# STM32L071 register map
File version: 1.3
CPU: CM0+ r0p0, little endian, no MPU, no FPU, 3 interrupt priority bits
Registers are 32-bit, read-write, reset 0x0 unless marked. A register's access mark holds for its fields unless they carry their own. Offsets are from the block's base; [hi:lo] are bit positions; {n}, {i} and the like mark numbered series; 'fields as' and 'values as' point back to an identical list.

## RTC — Real-time clock
Base 0x40002800
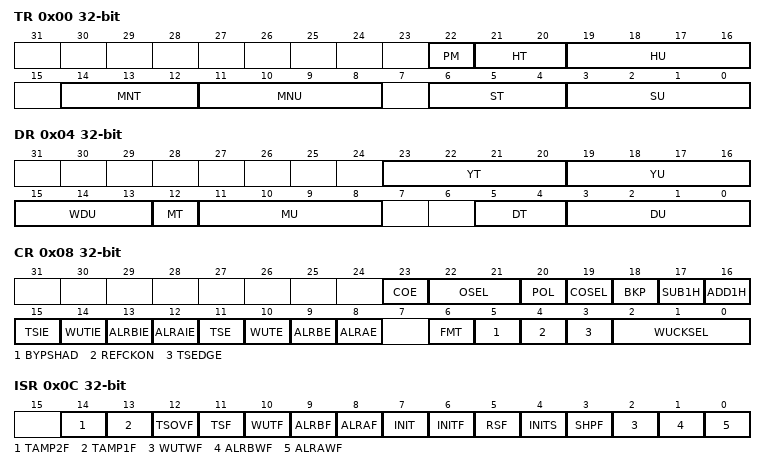
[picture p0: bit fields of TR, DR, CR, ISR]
0x00 TR — RTC time register
  [22] PM — AM/PM notation
  [21:20] HT — Hour tens in BCD format
  [19:16] HU — Hour units in BCD format
  [14:12] MNT — Minute tens in BCD format
  [11:8] MNU — Minute units in BCD format
  [6:4] ST — Second tens in BCD format
  [3:0] SU — Second units in BCD format
0x04 DR — RTC date register
  [23:20] YT — Year tens in BCD format
  [19:16] YU — Year units in BCD format
  [15:13] WDU — Week day units
  [12] MT — Month tens in BCD format
  [11:8] MU — Month units in BCD format
  [5:4] DT — Date tens in BCD format
  [3:0] DU — Date units in BCD format
0x08 CR access per field — RTC control register
  [23] COE rw — Calibration output enable
  [22:21] OSEL rw — Output selection
  [20] POL rw — Output polarity
  [19] COSEL rw — Calibration output selection
  [18] BKP rw — Backup
  [17] SUB1H wo — Subtract 1 hour (winter time change)
  [16] ADD1H wo — Add 1 hour (summer time change)
  [15] TSIE rw — Time-stamp interrupt enable
  [14] WUTIE rw — Wakeup timer interrupt enable
  [13] ALRBIE rw — Alarm B interrupt enable
  [12] ALRAIE rw — Alarm A interrupt enable
  [11] TSE rw — timestamp enable
  [10] WUTE rw — Wakeup timer enable
  [9] ALRBE rw — Alarm B enable
  [8] ALRAE rw — Alarm A enable
  [6] FMT rw — Hour format
  [5] BYPSHAD rw — Bypass the shadow registers
  [4] REFCKON rw — RTC_REFIN reference clock detection enable (50 or 60 Hz)
  [3] TSEDGE rw — Time-stamp event active edge
  [2:0] WUCKSEL rw — Wakeup clock selection
0x0C ISR access per field — RTC initialization and status register
  [14] TAMP2F rw — RTC_TAMP2 detection flag
  [13] TAMP1F rw — RTC_TAMP1 detection flag
  [12] TSOVF rw — Time-stamp overflow flag
  [11] TSF rw — Time-stamp flag
  [10] WUTF rw — Wakeup timer flag
  [9] ALRBF rw — Alarm B flag
  [8] ALRAF rw — Alarm A flag
  [7] INIT rw — Initialization mode
  [6] INITF ro — Initialization flag
  [5] RSF rw — Registers synchronization flag
  [4] INITS ro — Initialization status flag
  [3] SHPF ro — Shift operation pending
  [2] WUTWF ro — Wakeup timer write flag
  [1] ALRBWF ro — Alarm B write flag
  [0] ALRAWF ro — Alarm A write flag
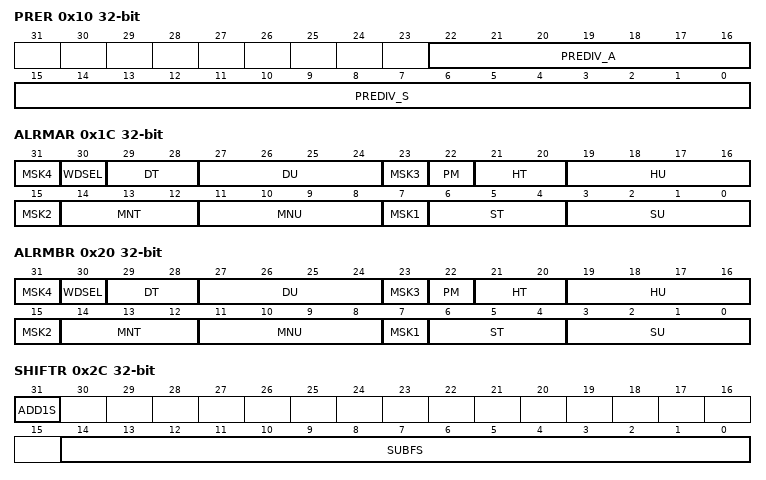
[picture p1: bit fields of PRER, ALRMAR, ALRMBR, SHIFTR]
0x10 PRER — RTC prescaler register
  [22:16] PREDIV_A — Asynchronous prescaler factor
  [15:0] PREDIV_S — Synchronous prescaler factor
0x14 WUTR — RTC wakeup timer register
  [15:0] WUT — Wakeup auto-reload value bits
0x1C ALRMAR — RTC alarm A register
  [31] MSK4 — Alarm A date mask
  [30] WDSEL — Week day selection
  [29:28] DT — Date tens in BCD format.
  [27:24] DU — Date units or day in BCD format.
  [23] MSK3 — Alarm A hours mask
  [22] PM — AM/PM notation
  [21:20] HT — Hour tens in BCD format.
  [19:16] HU — Hour units in BCD format.
  [15] MSK2 — Alarm A minutes mask
  [14:12] MNT — Minute tens in BCD format.
  [11:8] MNU — Minute units in BCD format.
  [7] MSK1 — Alarm A seconds mask
  [6:4] ST — Second tens in BCD format.
  [3:0] SU — Second units in BCD format.
0x20 ALRMBR — RTC alarm B register
  [31] MSK4 — Alarm B date mask
  [30] WDSEL — Week day selection
  [29:28] DT — Date tens in BCD format
  [27:24] DU — Date units or day in BCD format
  [23] MSK3 — Alarm B hours mask
  [22] PM — AM/PM notation
  [21:20] HT — Hour tens in BCD format
  [19:16] HU — Hour units in BCD format
  [15] MSK2 — Alarm B minutes mask
  [14:12] MNT — Minute tens in BCD format
  [11:8] MNU — Minute units in BCD format
  [7] MSK1 — Alarm B seconds mask
  [6:4] ST — Second tens in BCD format
  [3:0] SU — Second units in BCD format
0x24 WPR wo — write protection register
  [7:0] KEY — Write protection key
0x28 SSR ro — RTC sub second register
  [15:0] SS — Sub second value
0x2C SHIFTR wo — RTC shift control register
  [31] ADD1S — Add one second
  [14:0] SUBFS — Subtract a fraction of a second
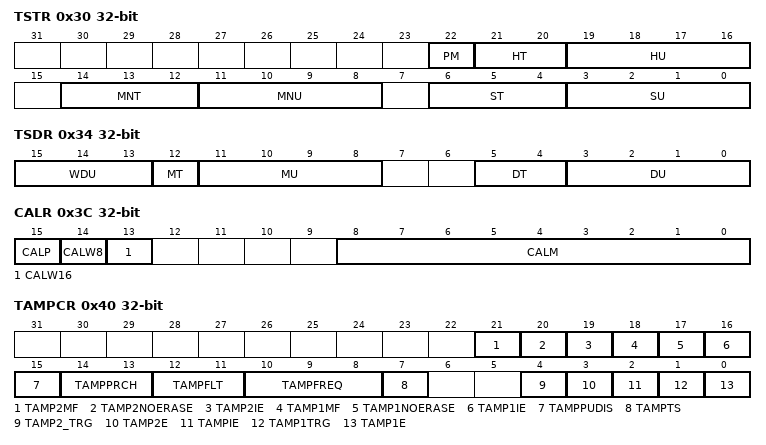
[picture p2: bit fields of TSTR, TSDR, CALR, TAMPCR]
0x30 TSTR ro — RTC timestamp time register
  [22] PM — AM/PM notation
  [21:20] HT — Hour tens in BCD format.
  [19:16] HU — Hour units in BCD format.
  [14:12] MNT — Minute tens in BCD format.
  [11:8] MNU — Minute units in BCD format.
  [6:4] ST — Second tens in BCD format.
  [3:0] SU — Second units in BCD format.
0x34 TSDR ro — RTC timestamp date register
  [15:13] WDU — Week day units
  [12] MT — Month tens in BCD format
  [11:8] MU — Month units in BCD format
  [5:4] DT — Date tens in BCD format
  [3:0] DU — Date units in BCD format
0x38 TSSSR ro — RTC time-stamp sub second register
  [15:0] SS — Sub second value
0x3C CALR — RTC calibration register
  [15] CALP — Increase frequency of RTC by 488.5 ppm
  [14] CALW8 — Use an 8-second calibration cycle period
  [13] CALW16 — Use a 16-second calibration cycle period
  [8:0] CALM — Calibration minus
0x40 TAMPCR — RTC tamper configuration register
  [21] TAMP2MF — Tamper 2 mask flag
  [20] TAMP2NOERASE — Tamper 2 no erase
  [19] TAMP2IE — Tamper 2 interrupt enable
  [18] TAMP1MF — Tamper 1 mask flag
  [17] TAMP1NOERASE — Tamper 1 no erase
  [16] TAMP1IE — Tamper 1 interrupt enable
  [15] TAMPPUDIS — RTC_TAMPx pull-up disable
  [14:13] TAMPPRCH — RTC_TAMPx precharge duration
  [12:11] TAMPFLT — RTC_TAMPx filter count
  [10:8] TAMPFREQ — Tamper sampling frequency
  [7] TAMPTS — Activate timestamp on tamper detection event
  [4] TAMP2_TRG — Active level for RTC_TAMP2 input
  [3] TAMP2E — RTC_TAMP2 input detection enable
  [2] TAMPIE — Tamper interrupt enable
  [1] TAMP1TRG — Active level for RTC_TAMP1 input
  [0] TAMP1E — RTC_TAMP1 input detection enable
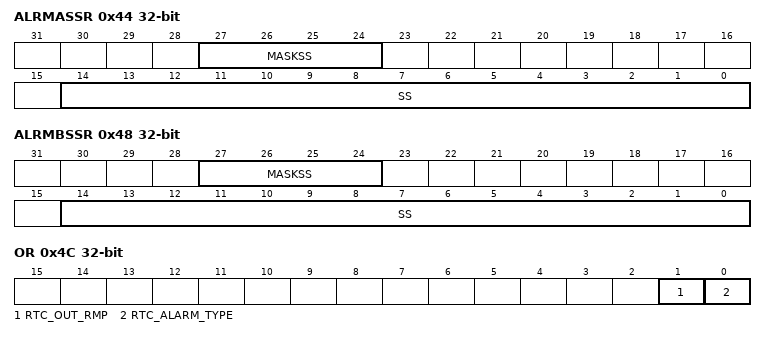
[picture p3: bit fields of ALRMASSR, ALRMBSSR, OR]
0x44 ALRMASSR — RTC alarm A sub second register
  [27:24] MASKSS — Mask the most-significant bits starting at this bit
  [14:0] SS — Sub seconds value
0x48 ALRMBSSR — RTC alarm B sub second register
  fields as ALRMASSR
0x4C OR — option register
  [1] RTC_OUT_RMP — RTC_ALARM on PC13 output type
  [0] RTC_ALARM_TYPE — RTC_ALARM on PC13 output type
{0x50+4i} BKP{i}R (i=0..4) — RTC backup registers
  [31:0] BKP
